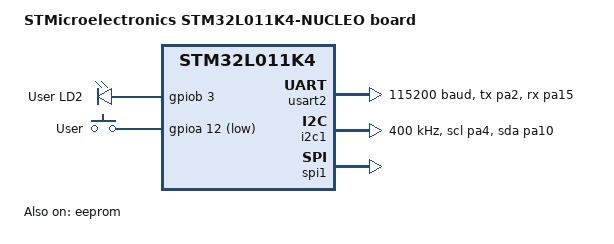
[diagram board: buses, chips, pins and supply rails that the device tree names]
/*
 * Copyright (c) 2020 Steven Daglish <s.c.daglish@gmail.com>
 *
 * SPDX-License-Identifier: Apache-2.0
 */

/dts-v1/;
#include <st/l0/stm32l011X4.dtsi>
#include <st/l0/stm32l011k(3-4)tx-pinctrl.dtsi>

/ {
	model = "STMicroelectronics STM32L011K4-NUCLEO board";
	compatible = "st,stm32l011k4-nucleo";

	chosen {
		zephyr,console = &usart2;
		zephyr,shell-uart = &usart2;
		zephyr,sram = &sram0;
		zephyr,flash = &flash0;
	};

	leds {
		compatible = "gpio-leds";
		green_led_2: led_2 {
			gpios = <&gpiob 3 GPIO_ACTIVE_HIGH>;
			label = "User LD2";
		};
	};

	gpio_keys {
		compatible = "gpio-keys";
		user_button: button {
			label = "User";
			gpios = <&gpioa 12 GPIO_ACTIVE_LOW>;
		};
	};

	aliases {
		led0 = &green_led_2;
		eeprom-0 = &eeprom;
	};
};

&usart2 {
	pinctrl-0 = <&usart2_tx_pa2 &usart2_rx_pa15>;
	current-speed = <115200>;
	status = "okay";
};

&i2c1 {
	pinctrl-0 = <&i2c1_scl_pa4 &i2c1_sda_pa10>;
	status = "okay";
	clock-frequency = <I2C_BITRATE_FAST>;
};

&spi1 {
	status = "okay";
};

&eeprom {
	status = "okay";
};
